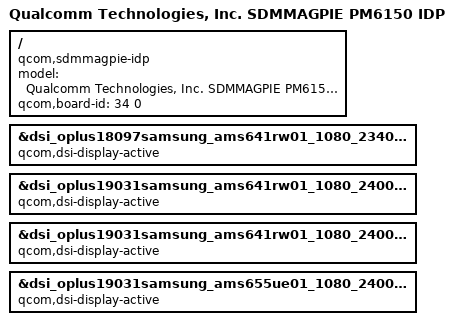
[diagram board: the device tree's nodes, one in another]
/* Copyright (c) 2018-2019, The Linux Foundation. All rights reserved.
 *
 * This program is free software; you can redistribute it and/or modify
 * it under the terms of the GNU General Public License version 2 and
 * only version 2 as published by the Free Software Foundation.
 *
 * This program is distributed in the hope that it will be useful,
 * but WITHOUT ANY WARRANTY; without even the implied warranty of
 * MERCHANTABILITY or FITNESS FOR A PARTICULAR PURPOSE.  See the
 * GNU General Public License for more details.
 */

/dts-v1/;

#include "sdmmagpie.dtsi"
#include "sdmmagpie-idp.dtsi"

/ {
	model = "Qualcomm Technologies, Inc. SDMMAGPIE PM6150 IDP";
	compatible = "qcom,sdmmagpie-idp", "qcom,sdmmagpie", "qcom,idp";
	qcom,board-id = <34 0>;
};

//#ifndef OPLUS_BUG_STABILITY
/*
&dsi_sw43404_amoled_video_display {
	qcom,dsi-display-active;
};
*/
//#else /* OPLUS_BUG_STABILITY */
&dsi_oplus18097samsung_ams641rw01_1080_2340_cmd_display {
	qcom,dsi-display-active;
};

&dsi_oplus19031samsung_ams641rw01_1080_2400_cmd_display {
	qcom,dsi-display-active;
};

&dsi_oplus19031samsung_ams641rw01_1080_2400_61fps_cmd_display {
	qcom,dsi-display-active;
};

&dsi_oplus19031samsung_ams655ue01_1080_2400_61fps_cmd_display {
	qcom,dsi-display-active;
};
//#endif /* OPLUS_BUG_STABILITY */
